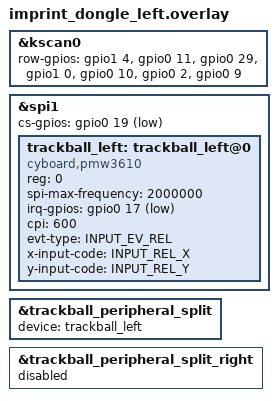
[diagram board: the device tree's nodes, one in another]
/* Left Half Peripheral: key matrix + left PMW3610 trackball */

#include "imprint_dongle.dtsi"

&kscan0 {
    row-gpios
        = <&gpio1 4 GPIO_ACTIVE_HIGH>
        , <&gpio0 11 GPIO_ACTIVE_HIGH>
        , <&gpio0 29 GPIO_ACTIVE_HIGH>
        , <&gpio1 0 GPIO_ACTIVE_HIGH>
        , <&gpio0 10 GPIO_ACTIVE_HIGH>
        , <&gpio0 2 GPIO_ACTIVE_HIGH>
        , <&gpio0 9 GPIO_ACTIVE_HIGH>
        ;
};

#include <zephyr/dt-bindings/input/input-event-codes.h>
&spi1 {
    cs-gpios = <&gpio0 19 GPIO_ACTIVE_LOW>;

    trackball_left: trackball_left@0 {
        status = "okay";
        compatible = "cyboard,pmw3610";
        reg = <0>;
        spi-max-frequency = <2000000>;
        irq-gpios = <&gpio0 17 (GPIO_ACTIVE_LOW | GPIO_PULL_UP)>;
        cpi = <600>;
        evt-type = <INPUT_EV_REL>;
        x-input-code = <INPUT_REL_X>;
        y-input-code = <INPUT_REL_Y>;
    };
};

/* Forward left trackball to central via channel 0 */
&trackball_peripheral_split {
    device = <&trackball_left>;
};

/* Disable the right-hand channel (not used on this peripheral) */
&trackball_peripheral_split_right {
    status = "disabled";
};
